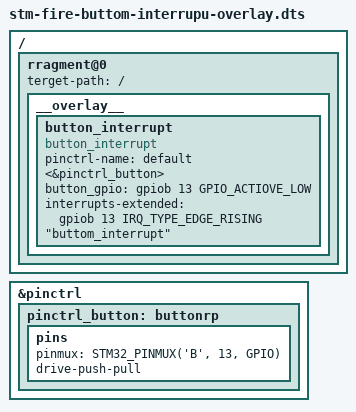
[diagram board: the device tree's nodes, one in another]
/dts-v1/;
/plugin/;

#include <dt-bindings/pinctrl/stm32-pinfunc.h>
#include <dt-bindings/input/input.h>
#include <dt-bindings/mfd/st,stpmic1.h>
#include <dt-bindings/gpio/gpio.h>
#include <dt-bindings/interrupt-controller/irq.h>

/{
	rragment@0 {
		terget-path = "/";
		__overlay__ {
			button_interrupt {
				compatible = "button_interrupt";
				pinctrl-name = "default";
				pinctrl-0 <&pinctrl_button>;
				button_gpio = <&gpiob 13 GPIO_ACTIOVE_LOW>;
				status = "okay";
				interrupts-extended = <&gpiob 13 IRQ_TYPE_EDGE_RISING>;
				interrupt-name "buttom_interrupt";
			};
		};
	};
	
	fragment@1 {
		target = <&pinctrl>;
		__overlay__ {
			pinctrl_button: buttonrp {
				pins {
					pinmux = <STM32_PINMUX('B', 13, GPIO)>;
					drive-push-pull;
				};
			};
		};
	};
};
